# UPD70F3508 register map
Vendor: Renesas; Series: V850E2/Px4; File version: 1.0
CPU: other r0p0, little endian, no MPU, FPU, 4 interrupt priority bits
Registers are 8-bit, read-write, reset 0x0 unless marked. A register's access mark holds for its fields unless they carry their own. Offsets are from the block's base; [hi:lo] are bit positions.

## TSG21 — TSG2 Three-phase PWM Timer 1 (Section 15)
Base 0xFF82F200
0x00 TS1IOC0 reset 0x7E — TSG2n I/O Control Register 0
  [6:1] TS1TOE6_1 — Enables/disables writing to TSnIOC2 for outputs TSG2nO6 to TSG2nO1 (bit per output)
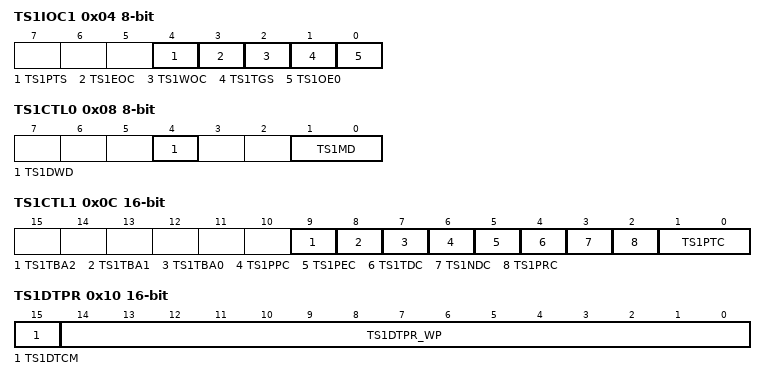
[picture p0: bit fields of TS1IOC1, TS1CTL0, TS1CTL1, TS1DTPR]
0x04 TS1IOC1 — TSG2n I/O Control Register 1
  [4] TS1PTS — Enables/disables edge detection signal (TSnPTE) and two-phase encoder count (TSnPEC) output
  [3] TS1EOC — Enables/disables error interrupt (INTTSG2nIER) detection
  [2] TS1WOC — Enables/disables warning interrupt (INTTSG2nIWN) detection
  [1] TS1TGS — Enables/disables diagnostic output
  [0] TS1OE0 — Enables/disables TSG2nO0 output
0x08 TS1CTL0 — TSG2n Control Register 0
  [4] TS1DWD — Selects the pulse width for the diagnostic output (0: 8 clocks, 1: 16 clocks)
  [1:0] TS1MD — Selects timer mode (00: PWM, 01: HT-PWM, 10: SP-PWM, 11: 120-DC)
0x0C TS1CTL1 16-bit — TSG2n Control Register 1
  [9] TS1TBA2 — Enables/disables simultaneous active state detection of TSG2nO5 and TSG2nO6
  [8] TS1TBA1 — Enables/disables simultaneous active state detection of TSG2nO3 and TSG2nO4
  [7] TS1TBA0 — Enables/disables simultaneous active state detection of TSG2nO1 and TSG2nO2
  [6] TS1PPC — Enables/disables pattern change detection interrupt (INTTSG2nIPC)
  [5] TS1PEC — Enables/disables two-phase encoder count interrupt (INTTSG2nIPEC)
  [4] TS1TDC — Enables/disables dead time compare error interrupt (INTTSG2nIDT)
  [3] TS1NDC — Enables/disables negative-side dead time compare error interrupt
  [2] TS1PRC — Enables/disables PWM output reload complete interrupt (INTTSG2nIPRC)
  [1:0] TS1PTC — Selects operation after detection of pattern change (PTC[1:0])
0x10 TS1DTPR 16-bit — TSG2n Dead Time Protection Register
  [15] TS1DTCM — Dead time register write protection (0: enable rewrite, 1: disable rewrite)
  [14:0] TS1DTPR_WP — Write protection code (0000H to 7FFFH)
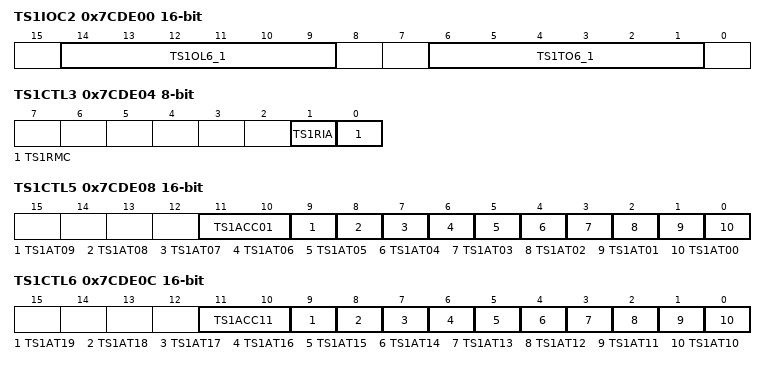
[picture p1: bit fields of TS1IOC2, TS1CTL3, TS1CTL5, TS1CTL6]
0x7CDE00 TS1IOC2 16-bit — TSG2n I/O Control Register 2
  [14:9] TS1OL6_1 — Active level for TSG2nO6 to TSG2nO1 (0: high, 1: low; one bit per output)
  [6:1] TS1TO6_1 — Latch level of output buffer for TSG2nO6 to TSG2nO1 (one bit per output)
0x7CDE04 TS1CTL3 — TSG2n Control Register 3
  [1] TS1RIA — Selects reload timing (0: peak/valley reload, 1: peak/valley interrupt)
  [0] TS1RMC — Selects compare register transfer timing (0: reload mode, 1: anytime rewrite)
0x7CDE08 TS1CTL5 16-bit — TSG2n Control Register 5
  [11:10] TS1ACC01 — Skipping rate for A/D trigger TSnADTRG0 (00: none, 01: 1/2, 10: 1/4, 11: 1/8)
  [9] TS1AT09 — Generate TSnADTRG0 at sub-counter peak (HT-PWM peak timing)
  [8] TS1AT08 — Generate TSnADTRG0 at sub-counter valley (HT-PWM valley timing)
  [7] TS1AT07 — Generate TSnADTRG0 at TSnDCMP2 match during decrement
  [6] TS1AT06 — Generate TSnADTRG0 at TSnDCMP2 match during increment
  [5] TS1AT05 — Generate TSnADTRG0 at TSnDCMP1 match during decrement (HT-PWM only)
  [4] TS1AT04 — Generate TSnADTRG0 at TSnDCMP1 match during increment
  [3] TS1AT03 — Generate TSnADTRG0 at TSnDCMP0 match during decrement (HT-PWM only)
  [2] TS1AT02 — Generate TSnADTRG0 at TSnDCMP0 match during increment
  [1] TS1AT01 — Generate TSnADTRG0 at peak interrupt timing
  [0] TS1AT00 — Generate TSnADTRG0 at valley interrupt timing
0x7CDE0C TS1CTL6 16-bit — TSG2n Control Register 6
  [11:10] TS1ACC11 — Skipping rate for A/D trigger TSnADTRG1 (00: none, 01: 1/2, 10: 1/4, 11: 1/8)
  [9] TS1AT19 — Generate TSnADTRG1 at sub-counter peak (HT-PWM peak timing)
  [8] TS1AT18 — Generate TSnADTRG1 at sub-counter valley (HT-PWM valley timing)
  [7] TS1AT17 — Generate TSnADTRG1 at TSnDCMP2 match during decrement
  [6] TS1AT16 — Generate TSnADTRG1 at TSnDCMP2 match during increment
  [5] TS1AT15 — Generate TSnADTRG1 at TSnDCMP1 match during decrement (HT-PWM only)
  [4] TS1AT14 — Generate TSnADTRG1 at TSnDCMP1 match during increment
  [3] TS1AT13 — Generate TSnADTRG1 at TSnDCMP0 match during decrement (HT-PWM only)
  [2] TS1AT12 — Generate TSnADTRG1 at TSnDCMP0 match during increment
  [1] TS1AT11 — Generate TSnADTRG1 at peak interrupt timing
  [0] TS1AT10 — Generate TSnADTRG1 at valley interrupt timing
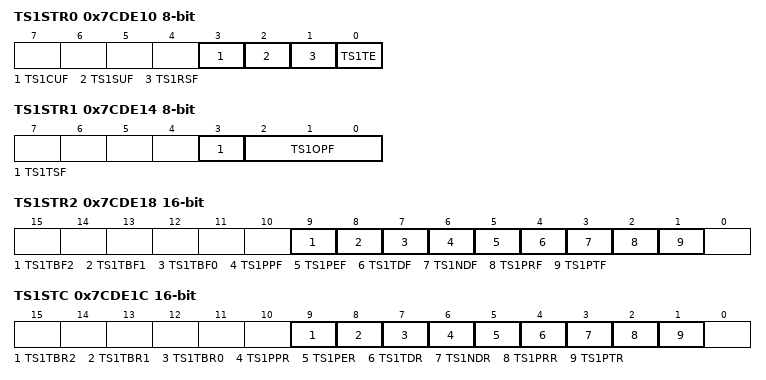
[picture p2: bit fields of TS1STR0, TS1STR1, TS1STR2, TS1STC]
0x7CDE10 TS1STR0 ro — TSG2n Status Register 0
  [3] TS1CUF — Count direction of 16-bit counter (0: incrementing, 1: decrementing; HT-PWM only)
  [2] TS1SUF — Count direction of 16-bit sub-counter (0: incrementing, 1: decrementing; HT-PWM only)
  [1] TS1RSF — Reload request flag (0: no request or complete, 1: pending; reload mode only)
  [0] TS1TE — TSG2n operation status (0: stopped, 1: operating)
0x7CDE14 TS1STR1 ro — TSG2n Status Register 1
  [3] TS1TSF — Pattern change order indicator (0: normal rotation, 1: reverse rotation)
  [2:0] TS1OPF — Output pattern of timer output pins TSG2nO1 to TSG2nO6 (OPF[2:0])
0x7CDE18 TS1STR2 16-bit ro — TSG2n Status Register 2
  [9] TS1TBF2 — Simultaneous active flag for TSG2nO5/TSG2nO6 (0: not simultaneous, 1: simultaneous)
  [8] TS1TBF1 — Simultaneous active flag for TSG2nO3/TSG2nO4
  [7] TS1TBF0 — Simultaneous active flag for TSG2nO1/TSG2nO2
  [6] TS1PPF — Pattern change detection flag
  [5] TS1PEF — Two-phase encoder count signal flag
  [4] TS1TDF — Dead time compare error flag (positive-side)
  [3] TS1NDF — Dead time compare error flag (negative-side)
  [2] TS1PRF — PWM reload complete flag
  [1] TS1PTF — Pattern change complete flag
0x7CDE1C TS1STC 16-bit wo — TSG2n Status Clear Trigger Register
  [9] TS1TBR2 — Clear trigger for TSnSTR2.TSnTBF2
  [8] TS1TBR1 — Clear trigger for TSnSTR2.TSnTBF1
  [7] TS1TBR0 — Clear trigger for TSnSTR2.TSnTBF0
  [6] TS1PPR — Clear trigger for TSnSTR2.TSnPPF
  [5] TS1PER — Clear trigger for TSnSTR2.TSnPEF
  [4] TS1TDR — Clear trigger for TSnSTR2.TSnTDF
  [3] TS1NDR — Clear trigger for TSnSTR2.TSnNDF
  [2] TS1PRR — Clear trigger for TSnSTR2.TSnPRF
  [1] TS1PTR — Clear trigger for TSnSTR2.TSnPTF
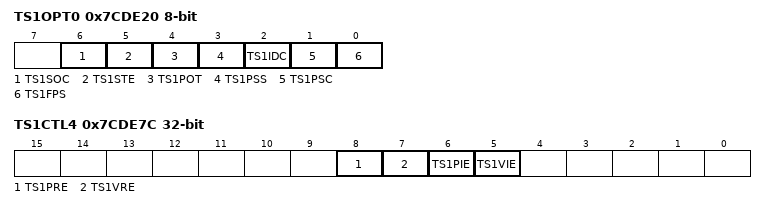
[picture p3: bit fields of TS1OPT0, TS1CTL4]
0x7CDE20 TS1OPT0 — TSG2n Option Register 0
  [6] TS1SOC — Enables/disables software control of timer output (TSG2nO1 to TSG2nO6)
  [5] TS1STE — Enables/disables pattern output trigger (TSG2nPTSI0-2 and TSnOPCI0-1 inputs)
  [4] TS1POT — Selects pattern output trigger (0: external pattern pins, 1: TSnOPCI0/1 edges)
  [3] TS1PSS — Enables pattern output order switch factor by TSnPSC
  [2] TS1IDC — Output pattern order determination factor
  [1] TS1PSC — Pattern output order switch control
  [0] TS1FPS — Selects fixed-pattern output or compare-match output
0x7CDE24 TS1OPT1 — TSG2n Option Register 1
  [2:0] TS1SPC — Timer output pattern for software output/120-DC mode (SPC[2:0])
0x7CDE28 TS1CNT 16-bit ro — TSG2n Counter Read Buffer Register
0x7CDE2C TS1SBC 16-bit ro — TSG2n Sub-Counter Read Buffer Register
0x7CDE30 TS1TRG0 wo — TSG2n Trigger Register 0
  [0] TS1TS — Timer start trigger (1: start/restart timer; always reads 0)
0x7CDE34 TS1TRG1 wo — TSG2n Trigger Register 1
  [0] TS1TT — Timer stop trigger (1: stop timer; always reads 0)
0x7CDE40 TS1CMP1W 32-bit — TSG2n Compare Register 1 and 2 (word)
0x7CDE44 TS1CMP5W 32-bit — TSG2n Compare Register 5 and 6 (word)
0x7CDE48 TS1CMP9W 32-bit — TSG2n Compare Register 9 and 10 (word)
0x7CDE4C TS1CMP3W 32-bit — TSG2n Compare Register 3 and 4 (word)
0x7CDE50 TS1CMP7W 32-bit — TSG2n Compare Register 7 and 8 (word)
0x7CDE54 TS1CMP11W 32-bit — TSG2n Compare Register 11 and 12 (word)
0x7CDE58 TS1CMP0 32-bit — TSG2n Compare Register 0
0x7CDE5C TS1DCMP0W 32-bit — TSG2n Diagnostic Output Compare Register 0 and 1
0x7CDE60 TS1DCMP2 32-bit — TSG2n Diagnostic Output Compare Register 2
0x7CDE64 TS1PAT0W 32-bit — TSG2n Pattern Register 0
0x7CDE68 TS1PAT1W 32-bit — TSG2n Pattern Register 1
0x7CDE6C TS1DTC0W 32-bit — TSG2n Dead Time Setting Register 0
0x7CDE70 TS1DTC1W 32-bit — TSG2n Dead Time Setting Register 1
0x7CDE74 TS1IOC3 32-bit — TSG2n I/O Control Register 3
  [6:1] TS1TOL6_1 — Set/clear level control for TSG2nO6 to TSG2nO1 (0: normal, 1: inverted)
0x7CDE78 TS1CTL2 32-bit — TSG2n Control Register 2
  [0] TS1CKS — Selects count clock (0: PCLK, 1: PCLK gated by TSG2nCLKI)
0x7CDE7C TS1CTL4 32-bit — TSG2n Control Register 4
  [8] TS1PRE — Enables/disables peak reload timing
  [7] TS1VRE — Enables/disables valley reload timing (valid in HT-PWM mode only)
  [6] TS1PIE — Enables/disables peak interrupt (INTTSG2nIPEK) generation
  [5] TS1VIE — Enables/disables valley interrupt (INTTSG2nIVLY) generation (HT-PWM only)
0x7CDE80 TS1CMP1 16-bit — TSG2n Compare Register 1
0x7CDE84 TS1CMP2 16-bit — TSG2n Compare Register 2
0x7CDE88 TS1CMP5 16-bit — TSG2n Compare Register 5
0x7CDE8C TS1CMP6 16-bit — TSG2n Compare Register 6
0x7CDE90 TS1CMP9 16-bit — TSG2n Compare Register 9
0x7CDE94 TS1CMP10 16-bit — TSG2n Compare Register 10
0x7CDE98 TS1CMP3 16-bit — TSG2n Compare Register 3
0x7CDE9C TS1CMP4 16-bit — TSG2n Compare Register 4
0x7CDEA0 TS1CMP7 16-bit — TSG2n Compare Register 7
0x7CDEA4 TS1CMP8 16-bit — TSG2n Compare Register 8
0x7CDEA8 TS1CMP11 16-bit — TSG2n Compare Register 11
0x7CDEAC TS1CMP12 16-bit — TSG2n Compare Register 12
0x7CDEB0 TS1CMPU 16-bit — TSG2n HT-PWM U Phase Compare Register
0x7CDEB4 TS1CMPV 16-bit — TSG2n HT-PWM V Phase Compare Register
0x7CDEB8 TS1CMPW 16-bit — TSG2n HT-PWM W Phase Compare Register
0x7CDEBC TS1UPW 16-bit — TSG2n SP-PWM U Phase Active Width Setting Register
0x7CDEC0 TS1VPW 16-bit — TSG2n SP-PWM V Phase Active Width Setting Register
0x7CDEC4 TS1WPW 16-bit — TSG2n SP-PWM W Phase Active Width Setting Register
